VERSION ""

NS_ :

BS_:

BU_: PRBMS

BO_ 26 New_Message_29: 8 Vector__XXX
 SG_ New_Signal_45 : 11|8@1+ (1,0) [0|0] "" Vector__XXX

BO_ 25 New_Message_28: 8 Vector__XXX
 SG_ New_Signal_44 : 12|8@1+ (1,0) [0|0] "" Vector__XXX

BO_ 24 New_Message_27: 8 Vector__XXX
 SG_ New_Signal_43 : 13|8@1+ (1,0) [0|0] "" Vector__XXX

BO_ 23 New_Message_26: 8 Vector__XXX
 SG_ New_Signal_42 : 14|8@1+ (1,0) [0|0] "" Vector__XXX

BO_ 22 New_Message_25: 8 Vector__XXX
 SG_ New_Signal_41 : 15|8@1+ (1,0) [0|0] "" Vector__XXX

BO_ 21 New_Message_24: 8 Vector__XXX
 SG_ New_Signal_40 : 0|8@1+ (1,0) [0|0] "" Vector__XXX

BO_ 20 New_Message_23: 8 Vector__XXX
 SG_ New_Signal_39 : 1|8@1+ (1,0) [0|0] "" Vector__XXX

BO_ 19 New_Message_22: 8 Vector__XXX
 SG_ New_Signal_38 : 2|8@1+ (1,0) [0|0] "" Vector__XXX

BO_ 18 New_Message_21: 8 Vector__XXX
 SG_ New_Signal_37 : 3|8@1+ (1,0) [0|0] "" Vector__XXX

BO_ 17 New_Message_20: 8 Vector__XXX
 SG_ New_Signal_36 : 4|8@1+ (1,0) [0|0] "" Vector__XXX

BO_ 16 New_Message_19: 8 Vector__XXX
 SG_ New_Signal_35 : 5|8@1+ (1,0) [0|0] "" Vector__XXX

BO_ 15 New_Message_18: 8 Vector__XXX
 SG_ New_Signal_34 : 6|8@1+ (1,0) [0|0] "" Vector__XXX

BO_ 14 New_Message_17: 8 Vector__XXX
 SG_ New_Signal_33 : 7|8@1+ (1,0) [0|0] "" Vector__XXX

BO_ 13 New_Message_16: 8 Vector__XXX
 SG_ New_Signal_32 : 12|8@1+ (1,0) [0|0] "" Vector__XXX

BO_ 12 New_Message_15: 8 Vector__XXX
 SG_ New_Signal_31 : 11|8@1+ (1,0) [0|0] "" Vector__XXX

BO_ 11 New_Message_14: 8 Vector__XXX
 SG_ New_Signal_30 : 10|8@1+ (1,0) [0|0] "" Vector__XXX

BO_ 10 New_Message_13: 8 Vector__XXX
 SG_ New_Signal_29 : 9|8@1+ (1,0) [0|0] "" Vector__XXX

BO_ 9 New_Message_12: 8 Vector__XXX
 SG_ New_Signal_28 : 8|8@1+ (1,0) [0|0] "" Vector__XXX

BO_ 8 New_Message_11: 8 Vector__XXX
 SG_ New_Signal_27 : 7|8@1+ (1,0) [0|0] "" Vector__XXX

BO_ 7 New_Message_10: 8 Vector__XXX
 SG_ New_Signal_26 : 6|8@1+ (1,0) [0|0] "" Vector__XXX

BO_ 6 New_Message_9: 8 Vector__XXX
 SG_ New_Signal_25 : 5|8@1+ (1,0) [0|0] "" Vector__XXX

BO_ 5 New_Message_8: 8 Vector__XXX
 SG_ New_Signal_24 : 4|8@1+ (1,0) [0|0] "" Vector__XXX

BO_ 4 New_Message_7: 8 Vector__XXX
 SG_ New_Signal_23 : 3|8@1+ (1,0) [0|0] "" Vector__XXX

BO_ 3 New_Message_6: 8 Vector__XXX
 SG_ New_Signal_22 : 2|8@1+ (1,0) [0|0] "" Vector__XXX

BO_ 2 New_Message_5: 8 Vector__XXX
 SG_ New_Signal_21 : 1|8@1+ (1,0) [0|0] "" Vector__XXX

BO_ 1 New_Message_4: 8 Vector__XXX
 SG_ New_Signal_20 : 0|8@1+ (1,0) [0|0] "" Vector__XXX

BO_ 0 New_Message_3: 8 Vector__XXX
 SG_ New_Signal_19 : 0|8@1+ (1,0) [0|0] "" Vector__XXX

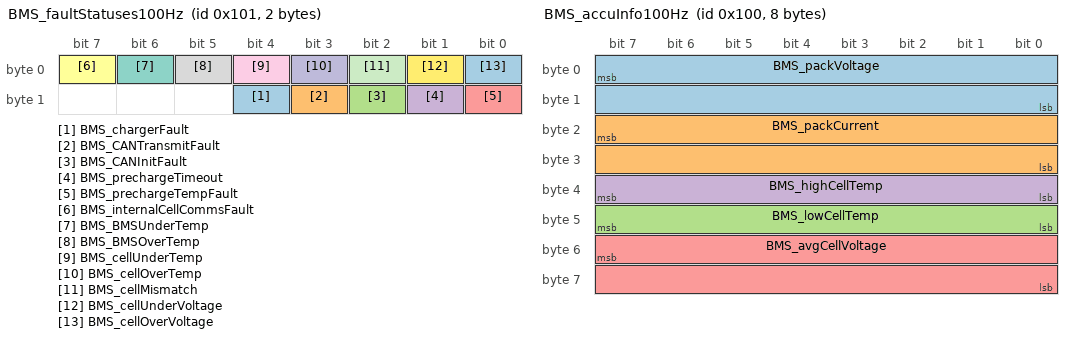
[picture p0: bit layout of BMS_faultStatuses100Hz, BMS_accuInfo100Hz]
BO_ 257 BMS_faultStatuses100Hz: 2 Vector__XXX
 SG_ BMS_chargerFault : 12|1@0+ (1,0) [0|0] "" Vector__XXX
 SG_ BMS_CANTransmitFault : 11|1@0+ (1,0) [0|0] "" Vector__XXX
 SG_ BMS_CANInitFault : 10|1@0+ (1,0) [0|0] "" Vector__XXX
 SG_ BMS_prechargeTimeout : 9|1@0+ (1,0) [0|0] "" Vector__XXX
 SG_ BMS_prechargeTempFault : 8|1@0+ (1,0) [0|0] "" Vector__XXX
 SG_ BMS_internalCellCommsFault : 7|1@0+ (1,0) [0|0] "" Vector__XXX
 SG_ BMS_BMSUnderTemp : 6|1@0+ (1,0) [0|0] "" Vector__XXX
 SG_ BMS_BMSOverTemp : 5|1@0+ (1,0) [0|0] "" Vector__XXX
 SG_ BMS_cellUnderTemp : 4|1@0+ (1,0) [0|0] "" Vector__XXX
 SG_ BMS_cellOverTemp : 3|1@0+ (1,0) [0|0] "" Vector__XXX
 SG_ BMS_cellMismatch : 2|1@0+ (1,0) [0|0] "" Vector__XXX
 SG_ BMS_cellUnderVoltage : 1|1@0+ (1,0) [0|0] "" Vector__XXX
 SG_ BMS_cellOverVoltage : 0|1@0+ (1,0) [0|1] "" Vector__XXX

BO_ 256 BMS_accuInfo100Hz: 8 PRBMS
 SG_ BMS_packVoltage : 7|16@0+ (0.1,0) [0|6553.5] "V" Vector__XXX
 SG_ BMS_packCurrent : 23|16@0+ (0.1,0) [0|6553.5] "A" Vector__XXX
 SG_ BMS_lowCellTemp : 47|8@0+ (1,0) [0|255] "C" Vector__XXX
 SG_ BMS_highCellTemp : 39|8@0+ (1,0) [0|255] "C" Vector__XXX
 SG_ BMS_avgCellVoltage : 55|16@0+ (0.001,0) [0|0] "V" Vector__XXX

BA_DEF_  "BusType" STRING ;
BA_DEF_DEF_  "BusType" "CAN";
